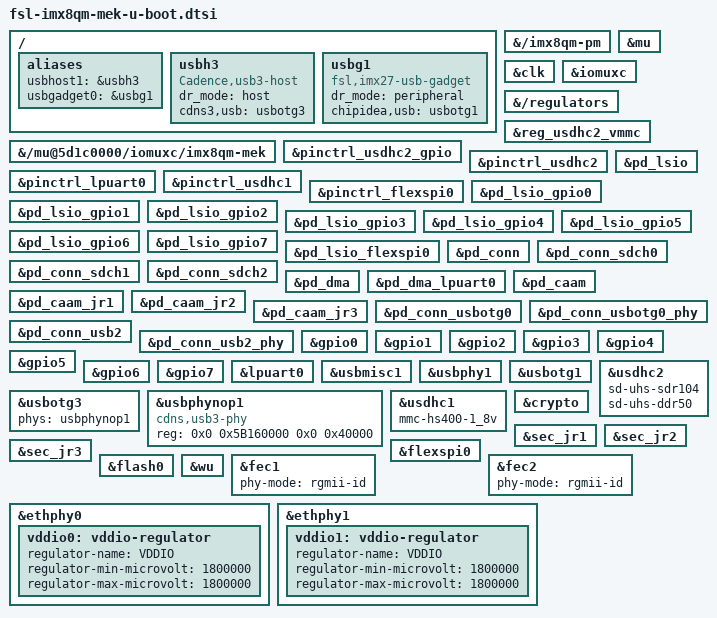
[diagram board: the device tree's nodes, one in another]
// SPDX-License-Identifier: GPL-2.0+
/*
 * Copyright 2018, 2021 NXP
 */

/ {

	aliases {
		usbhost1 = &usbh3;
		usbgadget0 = &usbg1;
	};

	usbh3: usbh3 {
		compatible = "Cadence,usb3-host";
		dr_mode = "host";
		cdns3,usb = <&usbotg3>;
		status = "okay";
	};

	usbg1: usbg1 {
		compatible = "fsl,imx27-usb-gadget";
		dr_mode = "peripheral";
		chipidea,usb = <&usbotg1>;
		status = "okay";
		u-boot,dm-spl;
	};
};

&{/imx8qm-pm} {

	bootph-pre-ram;
};

&mu {
	bootph-pre-ram;
};

&clk {
	bootph-pre-ram;
};

&iomuxc {
	bootph-pre-ram;
};

&{/regulators} {
	u-boot,dm-spl;
};

&reg_usdhc2_vmmc {
	u-boot,dm-spl;
};

&{/mu@5d1c0000/iomuxc/imx8qm-mek} {
	u-boot,dm-spl;
};

&pinctrl_usdhc2_gpio {
	u-boot,dm-spl;
};

&pinctrl_usdhc2 {
	u-boot,dm-spl;
};

&pinctrl_lpuart0 {
	u-boot,dm-spl;
};

&pinctrl_usdhc1 {
	u-boot,dm-spl;
};

&pinctrl_flexspi0 {
	u-boot,dm-spl;
};

&pd_lsio {
	bootph-pre-ram;
};

&pd_lsio_gpio0 {
	bootph-pre-ram;
};

&pd_lsio_gpio1 {
	bootph-pre-ram;
};

&pd_lsio_gpio2 {
	bootph-pre-ram;
};

&pd_lsio_gpio3 {
	bootph-pre-ram;
};

&pd_lsio_gpio4 {
	bootph-pre-ram;
};

&pd_lsio_gpio5 {
	bootph-pre-ram;
};

&pd_lsio_gpio6 {
	bootph-pre-ram;
};

&pd_lsio_gpio7 {
	bootph-pre-ram;
};

&pd_lsio_flexspi0 {
	u-boot,dm-spl;
};

&pd_conn {
	bootph-pre-ram;
};

&pd_conn_sdch0 {
	bootph-pre-ram;
};

&pd_conn_sdch1 {
	bootph-pre-ram;
};

&pd_conn_sdch2 {
	bootph-pre-ram;
};

&pd_dma {
	bootph-pre-ram;
};

&pd_dma_lpuart0 {
	bootph-pre-ram;
};

&pd_caam {
	bootph-pre-ram;
};

&pd_caam_jr1 {
	bootph-pre-ram;
};

&pd_caam_jr2 {
	bootph-pre-ram;
};

&pd_caam_jr3 {
	bootph-pre-ram;
};

&pd_conn_usbotg0 {
	u-boot,dm-spl;
};

&pd_conn_usbotg0_phy {
	u-boot,dm-spl;
};

&pd_conn_usb2 {
	u-boot,dm-spl;
};

&pd_conn_usb2_phy {
	u-boot,dm-spl;
};

&gpio0 {
	bootph-pre-ram;
};

&gpio1 {
	bootph-pre-ram;
};

&gpio2 {
	bootph-pre-ram;
};

&gpio3 {
	bootph-pre-ram;
};

&gpio4 {
	bootph-pre-ram;
};

&gpio5 {
	bootph-pre-ram;
};

&gpio6 {
	bootph-pre-ram;
};

&gpio7 {
	bootph-pre-ram;
};

&lpuart0 {
	bootph-pre-ram;
};

&usbmisc1 {
	u-boot,dm-spl;
};

&usbphy1 {
	u-boot,dm-spl;
};

&usbotg1 {
	u-boot,dm-spl;
};

&usbotg3 {
	phys = <&usbphynop1>;
	u-boot,dm-spl;
};

&usbphynop1 {
	compatible = "cdns,usb3-phy";
	reg = <0x0 0x5B160000 0x0 0x40000>;
	#phy-cells = <0>;
	u-boot,dm-spl;
};

&usdhc1 {
	bootph-pre-ram;
	mmc-hs400-1_8v;
};

&usdhc2 {
	bootph-pre-ram;
	sd-uhs-sdr104;
	sd-uhs-ddr50;
};

&crypto {
	bootph-pre-ram;
};

&sec_jr1 {
	bootph-pre-ram;
};

&sec_jr2 {
	bootph-pre-ram;
};

&sec_jr3 {
	bootph-pre-ram;
};

&flexspi0 {
	u-boot,dm-spl;
};

&flash0 {
	u-boot,dm-spl;
};

&wu {
	u-boot,dm-spl;
};

&fec1 {
	phy-mode = "rgmii-id";
};

&fec2 {
	phy-mode = "rgmii-id";
};

&ethphy0 {
	vddio0: vddio-regulator {
		regulator-name = "VDDIO";
		regulator-min-microvolt = <1800000>;
		regulator-max-microvolt = <1800000>;
	};
};

&ethphy1 {
	vddio1: vddio-regulator {
		regulator-name = "VDDIO";
		regulator-min-microvolt = <1800000>;
		regulator-max-microvolt = <1800000>;
	};
};
